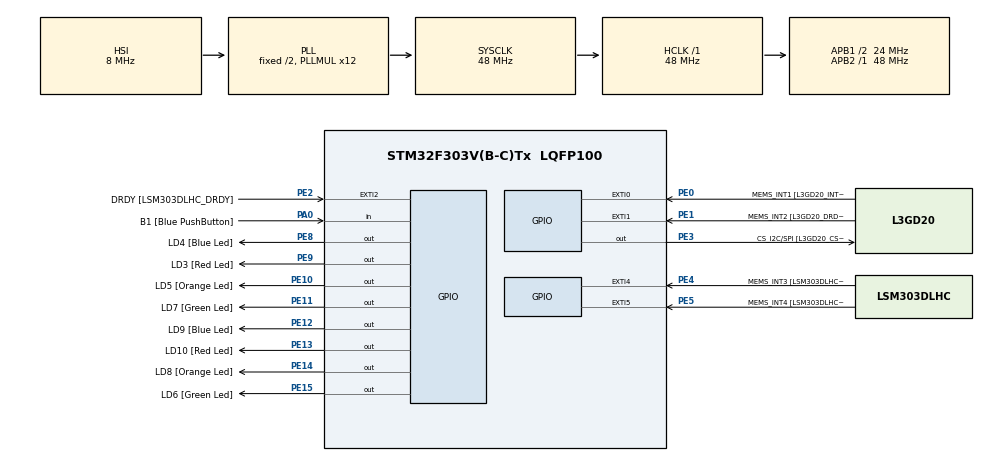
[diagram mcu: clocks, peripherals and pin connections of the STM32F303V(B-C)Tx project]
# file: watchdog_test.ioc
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FREERTOS.Tasks01=defaultTask,0,128,StartDefaultTask
FREERTOS.configMAX_PRIORITIES=255
Mcu.Family=STM32F3
Mcu.Name=STM32F303V(B-C)Tx
Mcu.Package=LQFP100
NVIC.PriorityGroup=NVIC_PRIORITYGROUP_4
PA0.GPIO_Label=B1 [Blue PushButton]
PA0.GPIO_Mode=GPIO_MODE_INPUT
PA0.GPIO_PuPd=GPIO_NOPULL
PA0.Signal=GPIO_Input
PA11.GPIO_Label=DM
PA11.Signal=USB_DM
PA12.GPIO_Label=DP
PA12.Signal=USB_DP
PA13.GPIO_Label=SWDIO
PA13.Mode=Trace-Asynchronous_SW
PA13.Signal=SYS_JTMS-SWDIO
PA14.GPIO_Label=SWCLK
PA14.Mode=Trace-Asynchronous_SW
PA14.Signal=SYS_JTCK-SWCLK
PA5.GPIO_Label=SPI1_SCK [L3GD20_SCL/SPC]
PA5.GPIO_Mode=GPIO_MODE_AF_PP
PA5.GPIO_PuPd=GPIO_NOPULL
PA5.GPIO_Speed=GPIO_SPEED_LOW
PA5.Signal=SPI1_SCK
PA6.GPIO_Label=SPI1_MISO [L3GD20_SA0/SDO]
PA6.GPIO_Mode=GPIO_MODE_AF_PP
PA6.GPIO_PuPd=GPIO_NOPULL
PA6.GPIO_Speed=GPIO_SPEED_LOW
PA6.Signal=SPI1_MISO
PA7.GPIO_Label=SPI1_MISO [L3GD20_SDA/SDI/SDO]
PA7.GPIO_Mode=GPIO_MODE_AF_PP
PA7.GPIO_PuPd=GPIO_NOPULL
PA7.GPIO_Speed=GPIO_SPEED_LOW
PA7.Signal=SPI1_MOSI
PB3.GPIO_Label=SWO
PB3.Mode=Trace-Asynchronous_SW
PB3.Signal=SYS_JTDO-TRACESWO
PB6.GPIO_FM6=__NULL
PB6.GPIO_Label=I2C1_SCL [LSM303DLHC_SCL]
PB6.GPIO_Mode=GPIO_MODE_AF_OD
PB6.GPIO_PuPd=GPIO_NOPULL
PB6.GPIO_Speed=GPIO_SPEED_LOW
PB6.Signal=I2C1_SCL
PB7.GPIO_FM7=__NULL
PB7.GPIO_Label=I2C1_SDA [LSM303DLHC_SDA]
PB7.GPIO_Mode=GPIO_MODE_AF_OD
PB7.GPIO_PuPd=GPIO_NOPULL
PB7.GPIO_Speed=GPIO_SPEED_LOW
PB7.Signal=I2C1_SDA
PC14-OSC32_IN.GPIO_Label=OSC32_IN
PC14-OSC32_IN.Signal=RCC_OSC32_IN
PC15-OSC32_OUT.GPIO_Label=OSC32_OUT
PC15-OSC32_OUT.Signal=RCC_OSC32_OUT
PE0.GPIO_Label=MEMS_INT1 [L3GD20_INT1]
PE0.GPIO_ModeDefaultEXTI=GPIO_MODE_EVT_RISING
PE0.GPIO_PuPd=GPIO_NOPULL
PE0.Signal=GPXTI0
PE1.GPIO_Label=MEMS_INT2 [L3GD20_DRDY/INT2]
PE1.GPIO_ModeDefaultEXTI=GPIO_MODE_EVT_RISING
PE1.GPIO_PuPd=GPIO_NOPULL
PE1.Signal=GPXTI1
PE10.GPIO_Label=LD5 [Orange Led]
PE10.GPIO_ModeDefaultOutputPP=GPIO_MODE_OUTPUT_PP
PE10.GPIO_PuPd=GPIO_NOPULL
PE10.GPIO_Speed=GPIO_SPEED_LOW
PE10.Signal=GPIO_Output
PE11.GPIO_Label=LD7 [Green Led]
PE11.GPIO_ModeDefaultOutputPP=GPIO_MODE_OUTPUT_PP
PE11.GPIO_PuPd=GPIO_NOPULL
PE11.GPIO_Speed=GPIO_SPEED_LOW
PE11.Signal=GPIO_Output
PE12.GPIO_Label=LD9 [Blue Led]
PE12.GPIO_ModeDefaultOutputPP=GPIO_MODE_OUTPUT_PP
PE12.GPIO_PuPd=GPIO_NOPULL
PE12.GPIO_Speed=GPIO_SPEED_LOW
PE12.Signal=GPIO_Output
PE13.GPIO_Label=LD10 [Red Led]
PE13.GPIO_ModeDefaultOutputPP=GPIO_MODE_OUTPUT_PP
PE13.GPIO_PuPd=GPIO_NOPULL
PE13.GPIO_Speed=GPIO_SPEED_LOW
PE13.Signal=GPIO_Output
PE14.GPIO_Label=LD8 [Orange Led]
PE14.GPIO_ModeDefaultOutputPP=GPIO_MODE_OUTPUT_PP
PE14.GPIO_PuPd=GPIO_NOPULL
PE14.GPIO_Speed=GPIO_SPEED_LOW
PE14.Signal=GPIO_Output
PE15.GPIO_Label=LD6 [Green Led]
PE15.GPIO_ModeDefaultOutputPP=GPIO_MODE_OUTPUT_PP
PE15.GPIO_PuPd=GPIO_NOPULL
PE15.GPIO_Speed=GPIO_SPEED_LOW
PE15.Signal=GPIO_Output
PE2.GPIO_Label=DRDY [LSM303DLHC_DRDY]
PE2.GPIO_ModeDefaultEXTI=GPIO_MODE_EVT_RISING
PE2.GPIO_PuPd=GPIO_NOPULL
PE2.Signal=GPXTI2
PE3.GPIO_Label=CS_I2C/SPI [L3GD20_CS_I2C/SPI]
PE3.GPIO_ModeDefaultOutputPP=GPIO_MODE_OUTPUT_PP
PE3.GPIO_PuPd=GPIO_NOPULL
PE3.GPIO_Speed=GPIO_SPEED_LOW
PE3.Signal=GPIO_Output
PE4.GPIO_Label=MEMS_INT3 [LSM303DLHC_INT1]
PE4.GPIO_ModeDefaultEXTI=GPIO_MODE_EVT_RISING
PE4.GPIO_PuPd=GPIO_NOPULL
PE4.Signal=GPXTI4
PE5.GPIO_Label=MEMS_INT4 [LSM303DLHC_INT2]
PE5.GPIO_ModeDefaultEXTI=GPIO_MODE_EVT_RISING
PE5.GPIO_PuPd=GPIO_NOPULL
PE5.Signal=GPXTI5
PE8.GPIO_Label=LD4 [Blue Led]
PE8.GPIO_ModeDefaultOutputPP=GPIO_MODE_OUTPUT_PP
PE8.GPIO_PuPd=GPIO_NOPULL
PE8.GPIO_Speed=GPIO_SPEED_LOW
PE8.Signal=GPIO_Output
PE9.GPIO_Label=LD3 [Red Led]
PE9.GPIO_ModeDefaultOutputPP=GPIO_MODE_OUTPUT_PP
PE9.GPIO_PuPd=GPIO_NOPULL
PE9.GPIO_Speed=GPIO_SPEED_LOW
PE9.Signal=GPIO_Output
PF0-OSC_IN.GPIO_Label=OSC_IN
PF0-OSC_IN.Signal=RCC_OSC_IN
PF1-OSC_OUT.GPIO_Label=OSC_OUT
PF1-OSC_OUT.Signal=RCC_OSC_OUT
ProjectManager.TargetToolchain=EWARM
RCC.AHBFreq_Value=48000000
RCC.APB1CLKDivider=RCC_HCLK_DIV2
RCC.APB1Freq_Value=24000000
RCC.APB1TimFreq_Value=48000000
RCC.APB2Freq_Value=48000000
RCC.APB2TimFreq_Value=48000000
RCC.CortexFreq_Value=48000000
RCC.HCLKFreq_Value=48000000
RCC.HSE_VALUE=8000000
RCC.HSI_VALUE=8000000
RCC.LSE_VALUE=32768
RCC.PLLMUL=RCC_PLL_MUL12
RCC.SYSCLKFreq_VALUE=48000000
RCC.SYSCLKSourceVirtual=RCC_SYSCLKSOURCE_PLLCLK
RCC.USBFreq_Value=48000000
VP_FREERTOS_VS_ENABLE.Mode=Enabled
VP_IWDG_VS_IWDG.Mode=IWDG_Activate
board=STM32F3DISCOVERY

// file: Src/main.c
/**
  *A spelendid example of a simple watchdog
  *
  **/
//#include "stm32f3xx_hal.h"
//#include "cmsis_os.h"
//#include <string.h>
#include "main.h"

//global for checkback
uint8_t gCheckback=0;

IWDG_HandleTypeDef hiwdg;
#define KICK_WATCHDOG hiwdg.Instance->KR=0xAAAA

osThreadId defaultTaskHandle;
osThreadId buttonTaskHandle;

//4 test threads for WD verification
osThreadId worker1TaskHandle;
osThreadId worker2TaskHandle;
osThreadId worker3TaskHandle;
osThreadId worker4TaskHandle;
osThreadId loadHandle;

void SystemClock_Config(void);
static void MX_GPIO_Init(void);
static void MX_IWDG_Init(void);
void StartDefaultTask(void const * argument);
void StartButtonTask(void const* argument);
void WorkerThread(void const* argument);
void loadHandleThread(void const* argument);

#include <stdio.h>

int main(void)
{

  /* MCU Configuration----------------------------------------------------------*/

  /* Reset of all peripherals, Initializes the Flash interface and the Systick. */

  //printf("reset :0x%x\n",rcc.CSR);
  HAL_Init();

  /* Configure the system clock */
  SystemClock_Config();
  RCC_TypeDef rcc;
  /* Initialize all configured peripherals */
  MX_GPIO_Init();

  if(__HAL_RCC_GET_FLAG(RCC_FLAG_IWDGRST)!=RESET){
    HAL_GPIO_WritePin(GPIOE,GPIO_PIN_8,GPIO_PIN_SET);
    __HAL_RCC_CLEAR_RESET_FLAGS();
    HAL_Delay(2000);
  }else{
    HAL_GPIO_WritePin(GPIOE,GPIO_PIN_8,GPIO_PIN_RESET);
    __HAL_RCC_CLEAR_RESET_FLAGS();
  }

  HAL_GPIO_WritePin(GPIOE,GPIO_PIN_9,GPIO_PIN_RESET);
  HAL_GPIO_WritePin(GPIOE,GPIO_PIN_11,GPIO_PIN_RESET);
  HAL_GPIO_WritePin(GPIOE,GPIO_PIN_13,GPIO_PIN_RESET);
  HAL_GPIO_WritePin(GPIOE,GPIO_PIN_15,GPIO_PIN_RESET);
  HAL_GPIO_WritePin(GPIOE,GPIO_PIN_8,GPIO_PIN_RESET);
  HAL_GPIO_WritePin(GPIOE,GPIO_PIN_10,GPIO_PIN_SET);
  HAL_Delay(2000);
  HAL_GPIO_WritePin(GPIOE,GPIO_PIN_10,GPIO_PIN_RESET);
  MX_IWDG_Init();

  osThreadDef(buttonTask, StartButtonTask, osPriorityRealtime,0,128);
  buttonTaskHandle = osThreadCreate(osThread(buttonTask),NULL);

  /*
  osThreadId worker1TaskHandle;
  osThreadId worker2TaskHandle;
  osThreadId worker3TaskHandle;
  osThreadId worker4TaskHandle;

  */
  HAL_GPIO_WritePin(GPIOE,GPIO_PIN_14,GPIO_PIN_RESET);
  static threadArgs args0;
  args0.led=GPIO_PIN_9;
  args0.id=0;
  args0.runningTime = 100;
  static threadArgs args1;
  args1.led=GPIO_PIN_11;
  args1.id  = 1;
  args1.runningTime=100;
  static threadArgs args2;
  args2.led = GPIO_PIN_13;
  args2.id  = 2;
  args2.runningTime=100;
  static threadArgs args3;
  args3.led = GPIO_PIN_15;
  args3.id  =3;
  args3.runningTime=100;

  osThreadDef(worker1, WorkerThread, osPriorityNormal,0,128);
  worker1TaskHandle= osThreadCreate(osThread(worker1),(void*)&args0);

  osThreadDef(worker2, WorkerThread, osPriorityNormal,0,128);
  worker2TaskHandle= osThreadCreate(osThread(worker2),(void*)&args1);

  osThreadDef(worker3, WorkerThread, osPriorityNormal,0,128);
  worker3TaskHandle= osThreadCreate(osThread(worker3),(void*)&args2);

  osThreadDef(worker4, WorkerThread, osPriorityNormal,0,128);
  worker4TaskHandle= osThreadCreate(osThread(worker4),(void*)&args3);

  //struct for the handler thread

  /*

typedef struct _threadInfo{
  uint32_t size;
  osThreadId* ID;
  void* ThreadDef;
}threadInfo;
  */

  threadInfo* tInfo     = pvPortMalloc(sizeof(threadInfo));
  tInfo->size           = 5;
  tInfo->ID             = pvPortMalloc(sizeof(osThreadId)*5);
  tInfo->tDef           = pvPortMalloc(sizeof(threadDef)*5);
  tInfo->arg            = (void*)pvPortMalloc(sizeof(void*)*5);

  //save thread handles. Take not that the order is the same
  //as the order they ack the loadHandler thread through gCheckback
  tInfo->ID[0]          = worker1TaskHandle;
  tInfo->ID[1]          = worker2TaskHandle;
  tInfo->ID[2]          = worker3TaskHandle;
  tInfo->ID[3]          = worker4TaskHandle;
  tInfo->ID[4]          = buttonTaskHandle;

  //copy thread data, note the order
  copy_osThreadDef_UD_t(&(tInfo->tDef[0]),(struct os_thread_def const*)&(os_thread_def_worker1));
  copy_osThreadDef_UD_t(&(tInfo->tDef[1]),(struct os_thread_def const*)&(os_thread_def_worker2));
  copy_osThreadDef_UD_t(&(tInfo->tDef[2]),(struct os_thread_def const*)&(os_thread_def_worker3));
  copy_osThreadDef_UD_t(&(tInfo->tDef[3]),(struct os_thread_def const*)&(os_thread_def_worker4));
  copy_osThreadDef_UD_t(&(tInfo->tDef[4]),(struct os_thread_def const*)&(os_thread_def_buttonTask));

  //copy thread arguments
  tInfo->arg[0]         = (void*)&args0;
  tInfo->arg[1]         = (void*)&args1;
  tInfo->arg[2]         = (void*)&args2;
  tInfo->arg[3]         = (void*)&args3;
  tInfo->arg[4]         = (void*)NULL;
  //creation of watchdog kicker
  osThreadDef(load, loadHandleThread, osPriorityRealtime,0,128);
  loadHandle = osThreadCreate(osThread(load),(void*)tInfo);

  /* Start scheduler */
  osKernelStart(NULL, NULL);

  /* We should never get here as control is now taken by the scheduler */

  /* Infinite loop */
  /* USER CODE BEGIN WHILE */
  while (1)
  {
  //do not put code here
  }
  /* USER CODE END 3 */

}

/** System Clock Configuration
*/
void SystemClock_Config(void)
{

  RCC_OscInitTypeDef RCC_OscInitStruct;
  RCC_ClkInitTypeDef RCC_ClkInitStruct;

  RCC_OscInitStruct.OscillatorType = RCC_OSCILLATORTYPE_HSI|RCC_OSCILLATORTYPE_LSI;
  RCC_OscInitStruct.HSIState = RCC_HSI_ON;
  RCC_OscInitStruct.HSICalibrationValue = 16;
  RCC_OscInitStruct.LSIState = RCC_LSI_ON;
  RCC_OscInitStruct.PLL.PLLState = RCC_PLL_ON;
  RCC_OscInitStruct.PLL.PLLSource = RCC_PLLSOURCE_HSI;
  RCC_OscInitStruct.PLL.PLLMUL = RCC_PLL_MUL12;
  HAL_RCC_OscConfig(&RCC_OscInitStruct);

  RCC_ClkInitStruct.ClockType = RCC_CLOCKTYPE_SYSCLK|RCC_CLOCKTYPE_PCLK1;
  RCC_ClkInitStruct.SYSCLKSource = RCC_SYSCLKSOURCE_PLLCLK;
  RCC_ClkInitStruct.AHBCLKDivider = RCC_SYSCLK_DIV1;
  RCC_ClkInitStruct.APB1CLKDivider = RCC_HCLK_DIV2;
  RCC_ClkInitStruct.APB2CLKDivider = RCC_HCLK_DIV1;
  HAL_RCC_ClockConfig(&RCC_ClkInitStruct, FLASH_LATENCY_1);

  HAL_SYSTICK_Config(HAL_RCC_GetHCLKFreq()/1000);

  HAL_SYSTICK_CLKSourceConfig(SYSTICK_CLKSOURCE_HCLK);

  /* SysTick_IRQn interrupt configuration */
  HAL_NVIC_SetPriority(SysTick_IRQn, 0, 0);
}

/* IWDG init function */
void MX_IWDG_Init(void)
{

  hiwdg.Instance = IWDG;
  hiwdg.Init.Prescaler = IWDG_PRESCALER_16;
  hiwdg.Init.Window = 4095;
  hiwdg.Init.Reload = 4095;
  HAL_IWDG_Init(&hiwdg);
}

/** Configure pins as
        * Analog
        * Input
        * Output
        * EVENT_OUT
        * EXTI
     PA5   ------> SPI1_SCK
     PA6   ------> SPI1_MISO
     PA7   ------> SPI1_MOSI
     PA11   ------> USB_DM
     PA12   ------> USB_DP
     PB6   ------> I2C1_SCL
     PB7   ------> I2C1_SDA
*/
void MX_GPIO_Init(void)
{

  GPIO_InitTypeDef GPIO_InitStruct;

  /* GPIO Ports Clock Enable */
  __GPIOE_CLK_ENABLE();
  __GPIOC_CLK_ENABLE();
  __GPIOF_CLK_ENABLE();
  __GPIOA_CLK_ENABLE();
  __GPIOB_CLK_ENABLE();

  /*Configure GPIO pins : DRDY_Pin MEMS_INT3_Pin MEMS_INT4_Pin MEMS_INT1_Pin
                           MEMS_INT2_Pin */
  GPIO_InitStruct.Pin = DRDY_Pin|MEMS_INT3_Pin|MEMS_INT4_Pin|MEMS_INT1_Pin
                          |MEMS_INT2_Pin;
  GPIO_InitStruct.Mode = GPIO_MODE_EVT_RISING;
  GPIO_InitStruct.Pull = GPIO_NOPULL;
  HAL_GPIO_Init(GPIOE, &GPIO_InitStruct);

  /*Configure GPIO pins : CS_I2C_SPI_Pin LD4_Pin LD3_Pin LD5_Pin
                           LD7_Pin LD9_Pin LD10_Pin LD8_Pin
                           LD6_Pin */
  GPIO_InitStruct.Pin = CS_I2C_SPI_Pin|LD4_Pin|LD3_Pin|LD5_Pin
                          |LD7_Pin|LD9_Pin|LD10_Pin|LD8_Pin
                          |LD6_Pin;
  GPIO_InitStruct.Mode = GPIO_MODE_OUTPUT_PP;
  GPIO_InitStruct.Pull = GPIO_NOPULL;
  GPIO_InitStruct.Speed = GPIO_SPEED_LOW;
  HAL_GPIO_Init(GPIOE, &GPIO_InitStruct);

  /*Configure GPIO pin : B1_Pin */
  GPIO_InitStruct.Pin = B1_Pin;
  GPIO_InitStruct.Mode = GPIO_MODE_INPUT;
  GPIO_InitStruct.Pull = GPIO_NOPULL;
  HAL_GPIO_Init(B1_GPIO_Port, &GPIO_InitStruct);

  /*Configure GPIO pins : PA5 PA6 SPI1_MISO_Pin */
  GPIO_InitStruct.Pin = GPIO_PIN_5|GPIO_PIN_6|SPI1_MISO_Pin;
  GPIO_InitStruct.Mode = GPIO_MODE_AF_PP;
  GPIO_InitStruct.Pull = GPIO_NOPULL;
  GPIO_InitStruct.Speed = GPIO_SPEED_LOW;
  GPIO_InitStruct.Alternate = GPIO_AF5_SPI1;
  HAL_GPIO_Init(GPIOA, &GPIO_InitStruct);

  /*Configure GPIO pins : DM_Pin DP_Pin */
  GPIO_InitStruct.Pin = DM_Pin|DP_Pin;
  GPIO_InitStruct.Mode = GPIO_MODE_AF_PP;
  GPIO_InitStruct.Pull = GPIO_NOPULL;
  GPIO_InitStruct.Speed = GPIO_SPEED_HIGH;
  GPIO_InitStruct.Alternate = GPIO_AF14_USB;
  HAL_GPIO_Init(GPIOA, &GPIO_InitStruct);

  /*Configure GPIO pins : PB6 PB7 */
  GPIO_InitStruct.Pin = GPIO_PIN_6|GPIO_PIN_7;
  GPIO_InitStruct.Mode = GPIO_MODE_AF_OD;
  GPIO_InitStruct.Pull = GPIO_PULLUP;
  GPIO_InitStruct.Speed = GPIO_SPEED_LOW;
  GPIO_InitStruct.Alternate = GPIO_AF4_I2C1;
  HAL_GPIO_Init(GPIOB, &GPIO_InitStruct);

}

void StartButtonTask(void const* argument){
  int dummy=-1;
  while(1){
    while((int)HAL_GPIO_ReadPin(GPIOA,GPIO_PIN_0)){
      HAL_Delay(1000);
    }
    gCheckback|=1<<4;
    osDelay(100);
  }

}

//worker thread
void WorkerThread(void const* argument){

  threadArgs* args = (threadArgs*)argument;
  uint16_t led  = args->led;
  uint8_t threadId = args->id;
  uint32_t runningTime = args->runningTime;

  gCheckback|=1<<threadId;
  while(1){
    HAL_GPIO_WritePin(GPIOE,led,GPIO_PIN_SET);
    HAL_Delay(runningTime);
    HAL_GPIO_WritePin(GPIOE,led,GPIO_PIN_RESET);
    HAL_Delay(runningTime);
    gCheckback |= 1<<threadId;
  }

}

void loadHandleThread(void const* arguments){
  threadInfo* tInfo = (threadInfo*)arguments;
  size_t size = tInfo->size;

 osDelay(400);
  while(1){

  uint8_t ack = gCheckback;
  if(ack == 0x1F){
    gCheckback=0;
    KICK_WATCHDOG;
    HAL_GPIO_WritePin(GPIOE,GPIO_PIN_14,GPIO_PIN_RESET);
    HAL_GPIO_WritePin(GPIOE,GPIO_PIN_12,GPIO_PIN_SET);
  }
  //shit probally hit the fan
  else{
    HAL_GPIO_WritePin(GPIOE,GPIO_PIN_12,GPIO_PIN_RESET);
    HAL_GPIO_WritePin(GPIOE,GPIO_PIN_14,GPIO_PIN_SET);

    for(int i = 0; i < size; i++){
      if( ((ack >> i)&0x1)  ==  0) {
        vTaskDelete(tInfo->ID[i]);
        osThreadCreate((osThreadDef_t*)&(tInfo->tDef[i]),*(tInfo->arg));
        break;
      }
    }
  }
  osDelay(400);
  }
}

/* StartDefaultTask function */
void StartDefaultTask(void const * argument)
{
  HAL_GPIO_WritePin(GPIOE,GPIO_PIN_8,GPIO_PIN_SET);
  osDelay(500);
  HAL_GPIO_WritePin(GPIOE,GPIO_PIN_8,GPIO_PIN_RESET);
  /* USER CODE BEGIN 5 */
  /* Infinite loop */
  for(;;)
  {
    HAL_GPIO_WritePin(GPIOE,GPIO_PIN_10,GPIO_PIN_SET);
    osDelay(100);
    HAL_GPIO_WritePin(GPIOE,GPIO_PIN_10,GPIO_PIN_RESET);
    osDelay(100);
  }
  /* USER CODE END 5 */
}

/************************ (C) COPYRIGHT STMicroelectronics *****END OF FILE****/
